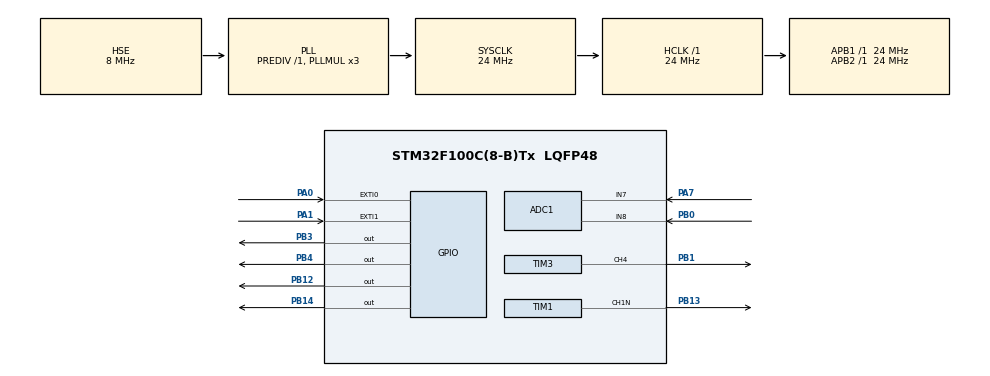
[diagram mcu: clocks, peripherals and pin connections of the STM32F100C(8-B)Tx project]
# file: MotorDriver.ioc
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ADC1.Channel-0\#ChannelRegularConversion=ADC_CHANNEL_8
ADC1.ContinuousConvMode=ENABLE
ADC1.DataAlign=ADC_DATAALIGN_RIGHT
ADC1.DiscontinuousConvMode=DISABLE
ADC1.EnableAnalogWatchDog=false
ADC1.EnableRegularConversion=ENABLE
ADC1.ExternalTrigConv=ADC_SOFTWARE_START
ADC1.InjNumberOfConversion=0
ADC1.NbrOfConversion=1
ADC1.NbrOfConversionFlag=1
ADC1.Rank-0\#ChannelRegularConversion=1
ADC1.SamplingTime-0\#ChannelRegularConversion=ADC_SAMPLETIME_41CYCLES_5
ADC1.ScanConvMode=ADC_SCAN_DISABLE
ADC1.master=1
Dma.ADC1.0.Direction=DMA_PERIPH_TO_MEMORY
Dma.ADC1.0.Instance=DMA1_Channel1
Dma.ADC1.0.MemDataAlignment=DMA_MDATAALIGN_HALFWORD
Dma.ADC1.0.MemInc=DMA_MINC_ENABLE
Dma.ADC1.0.Mode=DMA_CIRCULAR
Dma.ADC1.0.PeriphDataAlignment=DMA_PDATAALIGN_HALFWORD
Dma.ADC1.0.PeriphInc=DMA_PINC_DISABLE
Dma.ADC1.0.Priority=DMA_PRIORITY_LOW
Dma.Request0=ADC1
Mcu.Family=STM32F1
Mcu.Name=STM32F100C(8-B)Tx
Mcu.Package=LQFP48
Mcu.UserConstants=TIMER_PERIOD,1000;TIMER_PRESCALER,100
NVIC.ADC1_IRQn=true\:0\:0\:false\:false\:true\:true
NVIC.DMA1_Channel1_IRQn=true\:0\:0\:false\:false\:true\:false
NVIC.EXTI0_IRQn=true\:0\:0\:false\:false\:true\:true
NVIC.EXTI1_IRQn=true\:0\:0\:false\:false\:true\:true
NVIC.PriorityGroup=NVIC_PRIORITYGROUP_4
PA0-WKUP.GPIO_ModeDefaultEXTI=GPIO_MODE_IT_RISING_FALLING
PA0-WKUP.GPIO_PuPd=GPIO_PULLDOWN
PA0-WKUP.Signal=GPXTI0
PA1.GPIO_ModeDefaultEXTI=GPIO_MODE_IT_RISING_FALLING
PA1.GPIO_PuPd=GPIO_PULLDOWN
PA1.Signal=GPXTI1
PA13.Mode=Serial_Wire
PA13.Signal=SYS_JTMS-SWDIO
PA14.Mode=Serial_Wire
PA14.Signal=SYS_JTCK-SWCLK
PA7.Signal=ADCx_IN7
PB0.Signal=ADCx_IN8
PB1.Signal=S_TIM3_CH4
PB12.Signal=GPIO_Output
PB13.Mode=PWM Generation1 CH1N
PB13.Signal=TIM1_CH1N
PB14.Signal=GPIO_Output
PB3.Signal=GPIO_Output
PB4.Signal=GPIO_Output
PD0-OSC_IN.Mode=HSE-External-Oscillator
PD0-OSC_IN.Signal=RCC_OSC_IN
PD1-OSC_OUT.Mode=HSE-External-Oscillator
PD1-OSC_OUT.Signal=RCC_OSC_OUT
ProjectManager.HeapSize=0x200
ProjectManager.StackSize=0x400
ProjectManager.TargetToolchain=SW4STM32
RCC.AHBFreq_Value=24000000
RCC.APB1Freq_Value=24000000
RCC.APB1TimFreq_Value=24000000
RCC.APB2Freq_Value=24000000
RCC.APB2TimFreq_Value=24000000
RCC.HCLKFreq_Value=24000000
RCC.PLLMUL=RCC_PLL_MUL3
RCC.PLLSource=RCC_PLLSOURCE_HSE
RCC.SYSCLKFreq_VALUE=24000000
RCC.SYSCLKSource=RCC_SYSCLKSOURCE_PLLCLK
SH.ADCx_IN7.0=ADC1_IN7,IN7
SH.ADCx_IN8.0=ADC1_IN8,IN8
SH.S_TIM3_CH4.0=TIM3_CH4,PWM Generation4 CH4
TIM1.Channel-PWM\ Generation1\ CH1N=TIM_CHANNEL_1
TIM3.AutoReloadPreload=TIM_AUTORELOAD_PRELOAD_ENABLE
TIM3.Channel-PWM\ Generation4\ CH4=TIM_CHANNEL_4
TIM3.Period=TIMER_PERIOD
TIM3.Prescaler=TIMER_PRESCALER
VP_TIM3_VS_ClockSourceINT.Mode=Internal
board=custom

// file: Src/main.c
/* USER CODE BEGIN Header */
/**
  ******************************************************************************
  * @file           : main.c
  * @brief          : Main program body
  ******************************************************************************
  ** This notice applies to any and all portions of this file
  * that are not between comment pairs USER CODE BEGIN and
  * USER CODE END. Other portions of this file, whether
  * inserted by the user or by software development tools
  * are owned by their respective copyright owners.
  *
  * COPYRIGHT(c) 2019 STMicroelectronics
  *
  * Redistribution and use in source and binary forms, with or without modification,
  * are permitted provided that the following conditions are met:
  *   1. Redistributions of source code must retain the above copyright notice,
  *      this list of conditions and the following disclaimer.
  *   2. Redistributions in binary form must reproduce the above copyright notice,
  *      this list of conditions and the following disclaimer in the documentation
  *      and/or other materials provided with the distribution.
  *   3. Neither the name of STMicroelectronics nor the names of its contributors
  *      may be used to endorse or promote products derived from this software
  *      without specific prior written permission.
  *
  * THIS SOFTWARE IS PROVIDED BY THE COPYRIGHT HOLDERS AND CONTRIBUTORS "AS IS"
  * AND ANY EXPRESS OR IMPLIED WARRANTIES, INCLUDING, BUT NOT LIMITED TO, THE
  * IMPLIED WARRANTIES OF MERCHANTABILITY AND FITNESS FOR A PARTICULAR PURPOSE ARE
  * DISCLAIMED. IN NO EVENT SHALL THE COPYRIGHT HOLDER OR CONTRIBUTORS BE LIABLE
  * FOR ANY DIRECT, INDIRECT, INCIDENTAL, SPECIAL, EXEMPLARY, OR CONSEQUENTIAL
  * DAMAGES (INCLUDING, BUT NOT LIMITED TO, PROCUREMENT OF SUBSTITUTE GOODS OR
  * SERVICES; LOSS OF USE, DATA, OR PROFITS; OR BUSINESS INTERRUPTION) HOWEVER
  * CAUSED AND ON ANY THEORY OF LIABILITY, WHETHER IN CONTRACT, STRICT LIABILITY,
  * OR TORT (INCLUDING NEGLIGENCE OR OTHERWISE) ARISING IN ANY WAY OUT OF THE USE
  * OF THIS SOFTWARE, EVEN IF ADVISED OF THE POSSIBILITY OF SUCH DAMAGE.
  *
  ******************************************************************************
  */
/* USER CODE END Header */

#include "main.h"

/* USER CODE BEGIN Includes */
#include "common.h"
#include "main2.h"
/* USER CODE END Includes */

ADC_HandleTypeDef hadc1;
DMA_HandleTypeDef hdma_adc1;

TIM_HandleTypeDef htim1;
TIM_HandleTypeDef htim3;

/* USER CODE BEGIN PV */
/* Private variables ---------------------------------------------------------*/

/* USER CODE END PV */

void SystemClock_Config(void);
static void MX_GPIO_Init(void);
static void MX_DMA_Init(void);
static void MX_ADC1_Init(void);
static void MX_TIM3_Init(void);
static void MX_TIM1_Init(void);
/* USER CODE BEGIN PFP */
/* Private function prototypes -----------------------------------------------*/

/* USER CODE END PFP */

int main(void)
{

  /* MCU Configuration--------------------------------------------------------*/

  /* Reset of all peripherals, Initializes the Flash interface and the Systick. */
  HAL_Init();

  /* Configure the system clock */
  SystemClock_Config();

  /* Initialize all configured peripherals */
  MX_GPIO_Init();
  MX_DMA_Init();
  MX_ADC1_Init();
  MX_TIM3_Init();
  MX_TIM1_Init();
  /* USER CODE BEGIN 2 */
  initMain();
  loopMain();

  /* USER CODE END 2 */

  /* Infinite loop */
  while (1)
  {

  }
}

void SystemClock_Config(void)
{
  RCC_OscInitTypeDef RCC_OscInitStruct = {0};
  RCC_ClkInitTypeDef RCC_ClkInitStruct = {0};
  RCC_PeriphCLKInitTypeDef PeriphClkInit = {0};

  /**Initializes the CPU, AHB and APB busses clocks
  */
  RCC_OscInitStruct.OscillatorType = RCC_OSCILLATORTYPE_HSE;
  RCC_OscInitStruct.HSEState = RCC_HSE_ON;
  RCC_OscInitStruct.HSEPredivValue = RCC_HSE_PREDIV_DIV1;
  RCC_OscInitStruct.PLL.PLLState = RCC_PLL_ON;
  RCC_OscInitStruct.PLL.PLLSource = RCC_PLLSOURCE_HSE;
  RCC_OscInitStruct.PLL.PLLMUL = RCC_PLL_MUL3;
  if (HAL_RCC_OscConfig(&RCC_OscInitStruct) != HAL_OK)
  {
    Error_Handler();
  }
  /**Initializes the CPU, AHB and APB busses clocks
  */
  RCC_ClkInitStruct.ClockType = RCC_CLOCKTYPE_HCLK|RCC_CLOCKTYPE_SYSCLK
                              |RCC_CLOCKTYPE_PCLK1|RCC_CLOCKTYPE_PCLK2;
  RCC_ClkInitStruct.SYSCLKSource = RCC_SYSCLKSOURCE_PLLCLK;
  RCC_ClkInitStruct.AHBCLKDivider = RCC_SYSCLK_DIV1;
  RCC_ClkInitStruct.APB1CLKDivider = RCC_HCLK_DIV1;
  RCC_ClkInitStruct.APB2CLKDivider = RCC_HCLK_DIV1;

  if (HAL_RCC_ClockConfig(&RCC_ClkInitStruct, FLASH_LATENCY_0) != HAL_OK)
  {
    Error_Handler();
  }
  PeriphClkInit.PeriphClockSelection = RCC_PERIPHCLK_ADC;
  PeriphClkInit.AdcClockSelection = RCC_ADCPCLK2_DIV2;
  if (HAL_RCCEx_PeriphCLKConfig(&PeriphClkInit) != HAL_OK)
  {
    Error_Handler();
  }
}

static void MX_ADC1_Init(void)
{

  ADC_ChannelConfTypeDef sConfig = {0};

  /**Common config
  */
  hadc1.Instance = ADC1;
  hadc1.Init.ScanConvMode = ADC_SCAN_ENABLE;
  hadc1.Init.ContinuousConvMode = ENABLE;
  hadc1.Init.DiscontinuousConvMode = DISABLE;
  hadc1.Init.ExternalTrigConv = ADC_SOFTWARE_START;
  hadc1.Init.DataAlign = ADC_DATAALIGN_RIGHT;
  hadc1.Init.NbrOfConversion = 2;
  if (HAL_ADC_Init(&hadc1) != HAL_OK)
  {
    Error_Handler();
  }
  /**Configure Regular Channel
  */
  sConfig.Channel = ADC_CHANNEL_7;
  sConfig.Rank = ADC_REGULAR_RANK_1;
  sConfig.SamplingTime = ADC_SAMPLETIME_41CYCLES_5;
  if (HAL_ADC_ConfigChannel(&hadc1, &sConfig) != HAL_OK)
  {
    Error_Handler();
  }
  /**Configure Regular Channel
  */
  sConfig.Channel = ADC_CHANNEL_8;
  sConfig.Rank = ADC_REGULAR_RANK_2;
  sConfig.SamplingTime = ADC_SAMPLETIME_1CYCLE_5;
  if (HAL_ADC_ConfigChannel(&hadc1, &sConfig) != HAL_OK)
  {
    Error_Handler();
  }

}

static void MX_TIM1_Init(void)
{

  TIM_MasterConfigTypeDef sMasterConfig = {0};
  TIM_OC_InitTypeDef sConfigOC = {0};
  TIM_BreakDeadTimeConfigTypeDef sBreakDeadTimeConfig = {0};

  htim1.Instance = TIM1;
  htim1.Init.Prescaler = 0;
  htim1.Init.CounterMode = TIM_COUNTERMODE_UP;
  htim1.Init.Period = 0;
  htim1.Init.ClockDivision = TIM_CLOCKDIVISION_DIV1;
  htim1.Init.RepetitionCounter = 0;
  htim1.Init.AutoReloadPreload = TIM_AUTORELOAD_PRELOAD_DISABLE;
  if (HAL_TIM_PWM_Init(&htim1) != HAL_OK)
  {
    Error_Handler();
  }
  sMasterConfig.MasterOutputTrigger = TIM_TRGO_RESET;
  sMasterConfig.MasterSlaveMode = TIM_MASTERSLAVEMODE_DISABLE;
  if (HAL_TIMEx_MasterConfigSynchronization(&htim1, &sMasterConfig) != HAL_OK)
  {
    Error_Handler();
  }
  sConfigOC.OCMode = TIM_OCMODE_PWM1;
  sConfigOC.Pulse = 0;
  sConfigOC.OCPolarity = TIM_OCPOLARITY_HIGH;
  sConfigOC.OCNPolarity = TIM_OCNPOLARITY_HIGH;
  sConfigOC.OCFastMode = TIM_OCFAST_DISABLE;
  sConfigOC.OCIdleState = TIM_OCIDLESTATE_RESET;
  sConfigOC.OCNIdleState = TIM_OCNIDLESTATE_RESET;
  if (HAL_TIM_PWM_ConfigChannel(&htim1, &sConfigOC, TIM_CHANNEL_1) != HAL_OK)
  {
    Error_Handler();
  }
  sBreakDeadTimeConfig.OffStateRunMode = TIM_OSSR_DISABLE;
  sBreakDeadTimeConfig.OffStateIDLEMode = TIM_OSSI_DISABLE;
  sBreakDeadTimeConfig.LockLevel = TIM_LOCKLEVEL_OFF;
  sBreakDeadTimeConfig.DeadTime = 0;
  sBreakDeadTimeConfig.BreakState = TIM_BREAK_DISABLE;
  sBreakDeadTimeConfig.BreakPolarity = TIM_BREAKPOLARITY_HIGH;
  sBreakDeadTimeConfig.AutomaticOutput = TIM_AUTOMATICOUTPUT_DISABLE;
  if (HAL_TIMEx_ConfigBreakDeadTime(&htim1, &sBreakDeadTimeConfig) != HAL_OK)
  {
    Error_Handler();
  }
  HAL_TIM_MspPostInit(&htim1);

}

static void MX_TIM3_Init(void)
{

  TIM_ClockConfigTypeDef sClockSourceConfig = {0};
  TIM_MasterConfigTypeDef sMasterConfig = {0};
  TIM_OC_InitTypeDef sConfigOC = {0};

  htim3.Instance = TIM3;
  htim3.Init.Prescaler = TIMER_PRESCALER;
  htim3.Init.CounterMode = TIM_COUNTERMODE_UP;
  htim3.Init.Period = TIMER_PERIOD;
  htim3.Init.ClockDivision = TIM_CLOCKDIVISION_DIV1;
  htim3.Init.AutoReloadPreload = TIM_AUTORELOAD_PRELOAD_ENABLE;
  if (HAL_TIM_Base_Init(&htim3) != HAL_OK)
  {
    Error_Handler();
  }
  sClockSourceConfig.ClockSource = TIM_CLOCKSOURCE_INTERNAL;
  if (HAL_TIM_ConfigClockSource(&htim3, &sClockSourceConfig) != HAL_OK)
  {
    Error_Handler();
  }
  if (HAL_TIM_PWM_Init(&htim3) != HAL_OK)
  {
    Error_Handler();
  }
  sMasterConfig.MasterOutputTrigger = TIM_TRGO_RESET;
  sMasterConfig.MasterSlaveMode = TIM_MASTERSLAVEMODE_DISABLE;
  if (HAL_TIMEx_MasterConfigSynchronization(&htim3, &sMasterConfig) != HAL_OK)
  {
    Error_Handler();
  }
  sConfigOC.OCMode = TIM_OCMODE_PWM1;
  sConfigOC.Pulse = 0;
  sConfigOC.OCPolarity = TIM_OCPOLARITY_HIGH;
  sConfigOC.OCFastMode = TIM_OCFAST_DISABLE;
  if (HAL_TIM_PWM_ConfigChannel(&htim3, &sConfigOC, TIM_CHANNEL_4) != HAL_OK)
  {
    Error_Handler();
  }
  HAL_TIM_MspPostInit(&htim3);

}

static void MX_DMA_Init(void)
{
  /* DMA controller clock enable */
  __HAL_RCC_DMA1_CLK_ENABLE();

  /* DMA interrupt init */
  /* DMA1_Channel1_IRQn interrupt configuration */
  HAL_NVIC_SetPriority(DMA1_Channel1_IRQn, 0, 0);
  HAL_NVIC_EnableIRQ(DMA1_Channel1_IRQn);

}

static void MX_GPIO_Init(void)
{
  GPIO_InitTypeDef GPIO_InitStruct = {0};

  /* GPIO Ports Clock Enable */
  __HAL_RCC_GPIOD_CLK_ENABLE();
  __HAL_RCC_GPIOA_CLK_ENABLE();
  __HAL_RCC_GPIOB_CLK_ENABLE();

  /*Configure GPIO pin Output Level */
  HAL_GPIO_WritePin(GPIOB, GPIO_PIN_12|GPIO_PIN_14|GPIO_PIN_3|GPIO_PIN_4, GPIO_PIN_RESET);

  /*Configure GPIO pins : PA0 PA1 */
  GPIO_InitStruct.Pin = GPIO_PIN_0|GPIO_PIN_1;
  GPIO_InitStruct.Mode = GPIO_MODE_IT_RISING_FALLING;
  GPIO_InitStruct.Pull = GPIO_PULLDOWN;
  HAL_GPIO_Init(GPIOA, &GPIO_InitStruct);

  /*Configure GPIO pins : PB12 PB14 PB3 PB4 */
  GPIO_InitStruct.Pin = GPIO_PIN_12|GPIO_PIN_14|GPIO_PIN_3|GPIO_PIN_4;
  GPIO_InitStruct.Mode = GPIO_MODE_OUTPUT_PP;
  GPIO_InitStruct.Pull = GPIO_NOPULL;
  GPIO_InitStruct.Speed = GPIO_SPEED_FREQ_LOW;
  HAL_GPIO_Init(GPIOB, &GPIO_InitStruct);

  /* EXTI interrupt init*/
  HAL_NVIC_SetPriority(EXTI0_IRQn, 0, 0);
  HAL_NVIC_EnableIRQ(EXTI0_IRQn);

  HAL_NVIC_SetPriority(EXTI1_IRQn, 0, 0);
  HAL_NVIC_EnableIRQ(EXTI1_IRQn);

}

void Error_Handler(void)
{
  while(1)
  {
  }
}

/************************ (C) COPYRIGHT STMicroelectronics *****END OF FILE****/
